# BL808 register map
Vendor: Bouffalo Lab; File version: 0.1
Registers are 32-bit, read-write, reset 0x0 unless marked. A register's access mark holds for its fields unless they carry their own. Offsets are from the block's base; [hi:lo] are bit positions; {n}, {i} and the like mark numbered series.

## PDS_BASE — Sleep control (Power-down sleep?)
Base 0x2000E000
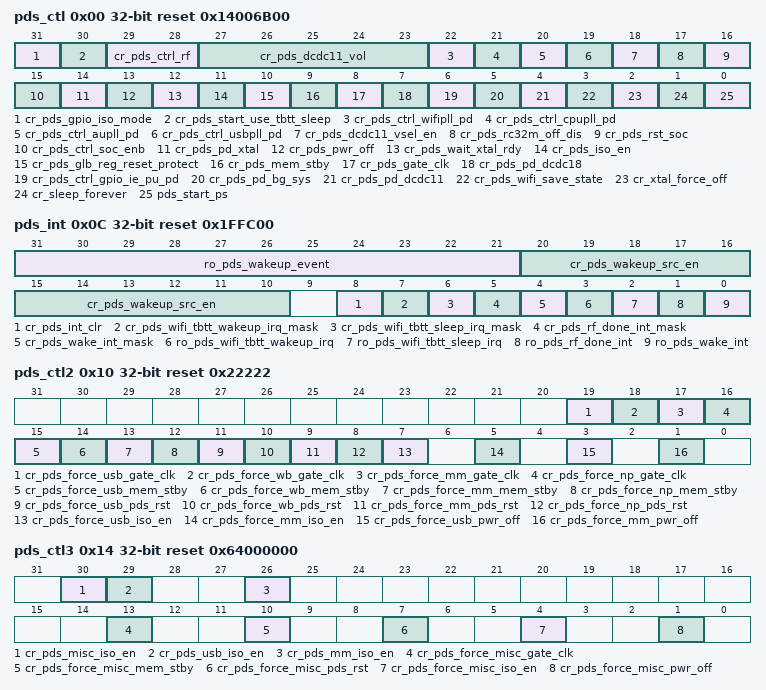
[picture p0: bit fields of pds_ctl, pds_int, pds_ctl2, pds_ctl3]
0x00 pds_ctl reset 0x14006B00
  [31] cr_pds_gpio_iso_mode, [30] cr_pds_start_use_tbtt_sleep, [29:28] cr_pds_ctrl_rf, [27:23] cr_pds_dcdc11_vol, [22] cr_pds_ctrl_wifipll_pd, [21] cr_pds_ctrl_cpupll_pd, [20] cr_pds_ctrl_aupll_pd, [19] cr_pds_ctrl_usbpll_pd, [18] cr_pds_dcdc11_vsel_en, [17] cr_pds_rc32m_off_dis, [16] cr_pds_rst_soc, [15] cr_pds_ctrl_soc_enb, [14] cr_pds_pd_xtal, [13] cr_pds_pwr_off, [12] cr_pds_wait_xtal_rdy, [11] cr_pds_iso_en, [10] cr_pds_glb_reg_reset_protect, [9] cr_pds_mem_stby, [8] cr_pds_gate_clk, [7] cr_pds_pd_dcdc18, [6] cr_pds_ctrl_gpio_ie_pu_pd, [5] cr_pds_pd_bg_sys, [4] cr_pds_pd_dcdc11, [3] cr_pds_wifi_save_state, [2] cr_xtal_force_off, [1] cr_sleep_forever, [0] pds_start_ps wo
0x04 pds_time1 reset 0xCA8
  [31:0] cr_sleep_duration
0x0C pds_int reset 0x1FFC00
  [31:21] ro_pds_wakeup_event ro, [20:10] cr_pds_wakeup_src_en, [8] cr_pds_int_clr, [7] cr_pds_wifi_tbtt_wakeup_irq_mask, [6] cr_pds_wifi_tbtt_sleep_irq_mask, [5] cr_pds_rf_done_int_mask, [4] cr_pds_wake_int_mask, [3] ro_pds_wifi_tbtt_wakeup_irq ro, [2] ro_pds_wifi_tbtt_sleep_irq ro, [1] ro_pds_rf_done_int ro, [0] ro_pds_wake_int ro
0x10 pds_ctl2 reset 0x22222
  [19] cr_pds_force_usb_gate_clk, [18] cr_pds_force_wb_gate_clk, [17] cr_pds_force_mm_gate_clk, [16] cr_pds_force_np_gate_clk, [15] cr_pds_force_usb_mem_stby, [14] cr_pds_force_wb_mem_stby, [13] cr_pds_force_mm_mem_stby, [12] cr_pds_force_np_mem_stby, [11] cr_pds_force_usb_pds_rst, [10] cr_pds_force_wb_pds_rst, [9] cr_pds_force_mm_pds_rst, [8] cr_pds_force_np_pds_rst, [7] cr_pds_force_usb_iso_en, [5] cr_pds_force_mm_iso_en, [3] cr_pds_force_usb_pwr_off, [1] cr_pds_force_mm_pwr_off
0x14 pds_ctl3 reset 0x64000000
  [30] cr_pds_misc_iso_en, [29] cr_pds_usb_iso_en, [26] cr_pds_mm_iso_en, [13] cr_pds_force_misc_gate_clk, [10] cr_pds_force_misc_mem_stby, [7] cr_pds_force_misc_pds_rst, [4] cr_pds_force_misc_iso_en, [1] cr_pds_force_misc_pwr_off
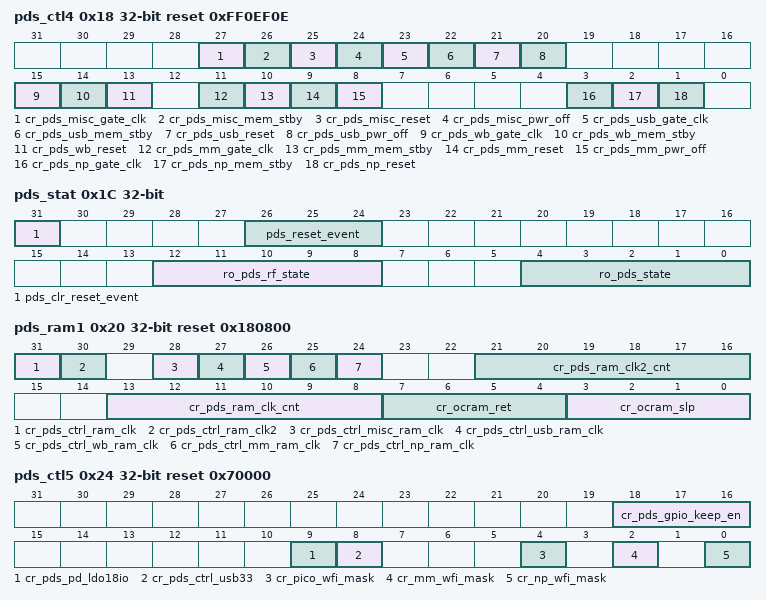
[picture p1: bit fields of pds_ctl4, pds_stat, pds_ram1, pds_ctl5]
0x18 pds_ctl4 reset 0xFF0EF0E
  [27] cr_pds_misc_gate_clk, [26] cr_pds_misc_mem_stby, [25] cr_pds_misc_reset, [24] cr_pds_misc_pwr_off, [23] cr_pds_usb_gate_clk, [22] cr_pds_usb_mem_stby, [21] cr_pds_usb_reset, [20] cr_pds_usb_pwr_off, [15] cr_pds_wb_gate_clk, [14] cr_pds_wb_mem_stby, [13] cr_pds_wb_reset, [11] cr_pds_mm_gate_clk, [10] cr_pds_mm_mem_stby, [9] cr_pds_mm_reset, [8] cr_pds_mm_pwr_off, [3] cr_pds_np_gate_clk, [2] cr_pds_np_mem_stby, [1] cr_pds_np_reset
0x1C pds_stat
  [31] pds_clr_reset_event wo, [26:24] pds_reset_event ro, [12:8] ro_pds_rf_state ro, [4:0] ro_pds_state ro
0x20 pds_ram1 reset 0x180800
  [31] cr_pds_ctrl_ram_clk, [30] cr_pds_ctrl_ram_clk2, [28] cr_pds_ctrl_misc_ram_clk, [27] cr_pds_ctrl_usb_ram_clk, [26] cr_pds_ctrl_wb_ram_clk, [25] cr_pds_ctrl_mm_ram_clk, [24] cr_pds_ctrl_np_ram_clk, [21:16] cr_pds_ram_clk2_cnt, [13:8] cr_pds_ram_clk_cnt, [7:4] cr_ocram_ret, [3:0] cr_ocram_slp
0x24 pds_ctl5 reset 0x70000
  [18:16] cr_pds_gpio_keep_en, [9] cr_pds_pd_ldo18io, [8] cr_pds_ctrl_usb33, [4] cr_pico_wfi_mask, [2] cr_mm_wfi_mask, [0] cr_np_wfi_mask
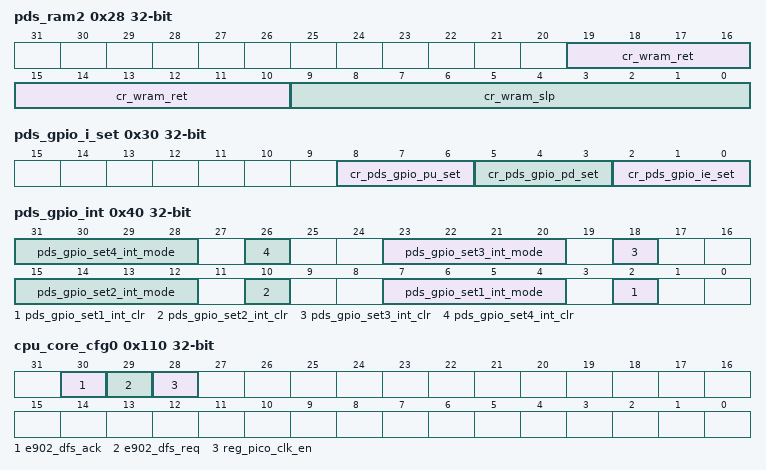
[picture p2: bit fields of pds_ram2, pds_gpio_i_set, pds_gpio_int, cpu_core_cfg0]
0x28 pds_ram2
  [19:10] cr_wram_ret, [9:0] cr_wram_slp
0x30 pds_gpio_i_set
  [8:6] cr_pds_gpio_pu_set, [5:3] cr_pds_gpio_pd_set, [2:0] cr_pds_gpio_ie_set
0x34 pds_gpio_pd_set reset 0xFFFFFFFF
  [31:0] cr_pds_gpio_set_int_mask
0x40 pds_gpio_int
  [8n-1:8n-4] pds_gpio_set{n}_int_mode (n=1..4), [8n-6] pds_gpio_set{n}_int_clr (n=1..4)
0x44 pds_gpio_stat
  [31:0] pds_gpio_int_stat ro
0x110 cpu_core_cfg0
  [30] e902_dfs_ack ro, [29] e902_dfs_req, [28] reg_pico_clk_en
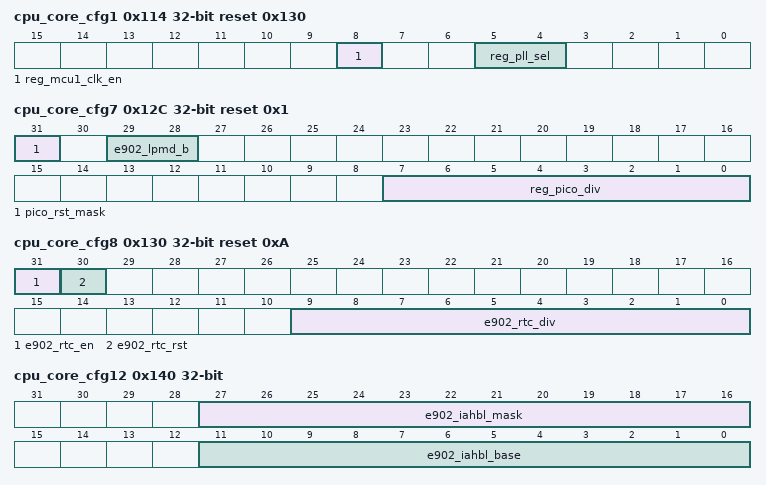
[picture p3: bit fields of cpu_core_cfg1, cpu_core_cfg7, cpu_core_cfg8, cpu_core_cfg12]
0x114 cpu_core_cfg1 reset 0x130
  [8] reg_mcu1_clk_en, [5:4] reg_pll_sel
0x12C cpu_core_cfg7 reset 0x1
  [31] pico_rst_mask, [29:28] e902_lpmd_b ro, [7:0] reg_pico_div
0x130 cpu_core_cfg8 reset 0xA
  [31] e902_rtc_en, [30] e902_rtc_rst, [9:0] e902_rtc_div
0x134 cpu_core_cfg9
  [31:0] pico_rtc_cnt_l ro
0x138 cpu_core_cfg10
  [31:0] pico_rtc_cnt_h ro
0x140 cpu_core_cfg12
  [27:16] e902_iahbl_mask, [11:0] e902_iahbl_base
0x144 cpu_core_cfg13 reset 0x22010000
  [31:0] e902_rst_addr
0x148 cpu_core_cfg14 reset 0x90000000
  [31:0] e906_rst_addr
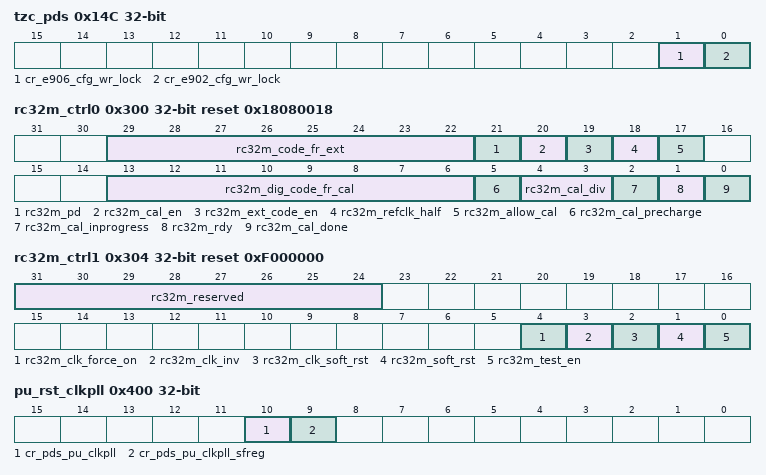
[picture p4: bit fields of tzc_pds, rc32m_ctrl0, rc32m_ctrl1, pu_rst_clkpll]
0x14C tzc_pds
  [1] cr_e906_cfg_wr_lock, [0] cr_e902_cfg_wr_lock
0x300 rc32m_ctrl0 reset 0x18080018
  [29:22] rc32m_code_fr_ext, [21] rc32m_pd, [20] rc32m_cal_en, [19] rc32m_ext_code_en, [18] rc32m_refclk_half, [17] rc32m_allow_cal, [13:6] rc32m_dig_code_fr_cal ro, [5] rc32m_cal_precharge ro, [4:3] rc32m_cal_div, [2] rc32m_cal_inprogress ro, [1] rc32m_rdy ro, [0] rc32m_cal_done ro
0x304 rc32m_ctrl1 reset 0xF000000
  [31:24] rc32m_reserved, [4] rc32m_clk_force_on, [3] rc32m_clk_inv, [2] rc32m_clk_soft_rst, [1] rc32m_soft_rst, [0] rc32m_test_en
0x400 pu_rst_clkpll
  [10] cr_pds_pu_clkpll, [9] cr_pds_pu_clkpll_sfreg
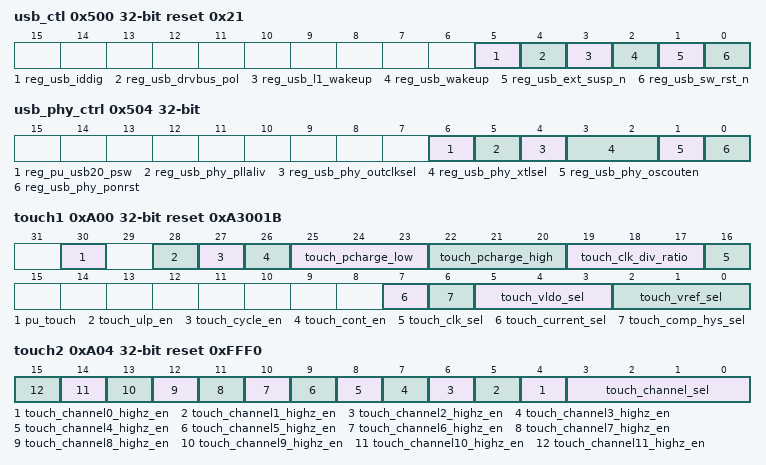
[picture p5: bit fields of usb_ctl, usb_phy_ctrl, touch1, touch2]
0x500 usb_ctl reset 0x21
  [5] reg_usb_iddig, [4] reg_usb_drvbus_pol, [3] reg_usb_l1_wakeup, [2] reg_usb_wakeup, [1] reg_usb_ext_susp_n, [0] reg_usb_sw_rst_n
0x504 usb_phy_ctrl
  [6] reg_pu_usb20_psw, [5] reg_usb_phy_pllaliv, [4] reg_usb_phy_outclksel, [3:2] reg_usb_phy_xtlsel, [1] reg_usb_phy_oscouten, [0] reg_usb_phy_ponrst
0xA00 touch1 reset 0xA3001B — touch channel, clock, ana config1
  [30] pu_touch, [28] touch_ulp_en, [27] touch_cycle_en, [26] touch_cont_en, [25:23] touch_pcharge_low, [22:20] touch_pcharge_high, [19:17] touch_clk_div_ratio, [16] touch_clk_sel, [7] touch_current_sel, [6] touch_comp_hys_sel, [5:3] touch_vldo_sel, [2:0] touch_vref_sel
0xA04 touch2 reset 0xFFF0 — touch channel, clock, ana config2
  [n+4] touch_channel{n}_highz_en (n=0..11), [3:0] touch_channel_sel
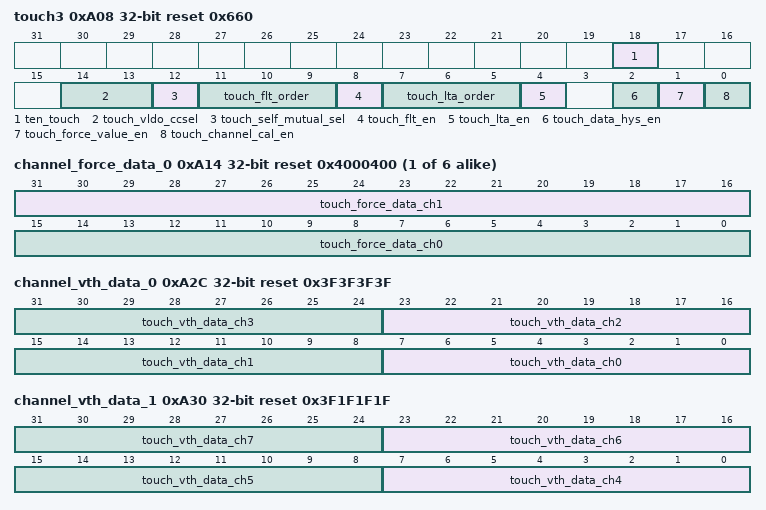
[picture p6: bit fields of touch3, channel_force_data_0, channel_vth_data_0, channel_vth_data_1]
0xA08 touch3 reset 0x660 — touch data process
  [18] ten_touch, [14:13] touch_vldo_ccsel, [12] touch_self_mutual_sel, [11:9] touch_flt_order, [8] touch_flt_en, [7:5] touch_lta_order, [4] touch_lta_en, [2] touch_data_hys_en, [1] touch_force_value_en, [0] touch_channel_cal_en
0xA0C touch_sleep_time reset 0x7FFFF
  [22:0] touch_sleep_cycle
0xA10 touch_data_hystersis
  [8:0] touch_data_hys
{0xA14+4i} channel_force_data_{i} reset 0x4000400 (i=0..5)
  [31:16] touch_force_data_ch{2i+1}, [15:0] touch_force_data_ch{2i}
0xA2C channel_vth_data_0 reset 0x3F3F3F3F
  [8n+7:8n] touch_vth_data_ch{n} (n=0..3)
0xA30 channel_vth_data_1 reset 0x3F1F1F1F
  [8n-25:8n-32] touch_vth_data_ch{n} (n=4..7)
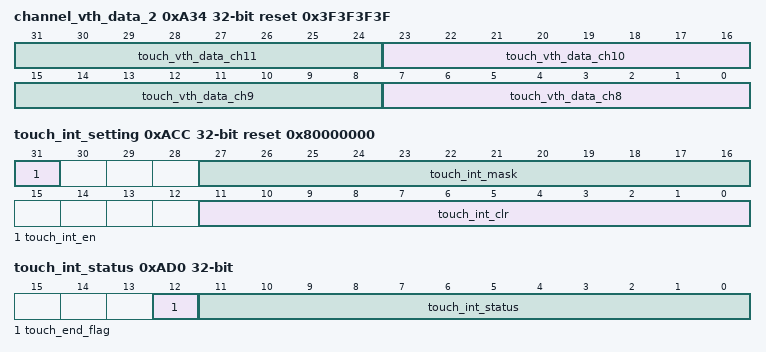
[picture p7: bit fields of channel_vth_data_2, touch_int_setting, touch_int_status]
0xA34 channel_vth_data_2 reset 0x3F3F3F3F
  [8n-57:8n-64] touch_vth_data_ch{n} (n=8..11)
{0xA38+4i} channel_raw_data_{i} (i=0..11)
  [15:0] touch_raw_data_ch{i} ro
{0xA68+4i} channel_lta_data_{i} (i=0..11)
  [15:0] touch_lta_data_ch{i} ro
{0xA98+4i} channel_flt_data_{i} (i=0..11)
  [15:0] touch_flt_data_ch{i} ro
0xAC8 touch_rsvd
  [7:0] touch_reserved
0xACC touch_int_setting reset 0x80000000
  [31] touch_int_en, [27:16] touch_int_mask, [11:0] touch_int_clr
0xAD0 touch_int_status
  [12] touch_end_flag ro, [11:0] touch_int_status ro
